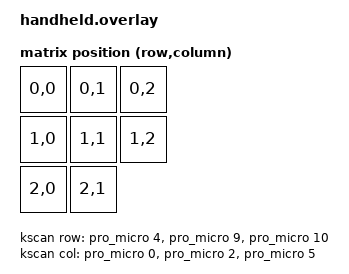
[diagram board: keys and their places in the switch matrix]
// This file was generated from a template. Edit it to match your keyboard.
// See https://zmk.dev/docs/development/hardware-integration/new-shield for more
// instructions.

#include <dt-bindings/zmk/matrix_transform.h>

#include "handheld-layouts.dtsi"

/ {
    chosen {
        zmk,physical-layout = &default_layout;
    };

    kscan: kscan {
        compatible = "zmk,kscan-gpio-matrix";
        diode-direction = "col2row";
        wakeup-source;

        // Replace these comments with the GPIO pins in the matrix.
        // See https://zmk.dev/docs/development/hardware-integration/new-shield#shield-overlays
        col-gpios
            = <&pro_micro 0 GPIO_ACTIVE_HIGH>
            , <&pro_micro 2 GPIO_ACTIVE_HIGH>
            , <&pro_micro 5 GPIO_ACTIVE_HIGH>
            ;

        row-gpios
            = <&pro_micro 4 (GPIO_ACTIVE_HIGH | GPIO_PULL_DOWN)>
            , <&pro_micro 9 (GPIO_ACTIVE_LOW | GPIO_PULL_DOWN)> 
            , <&pro_micro 10 (GPIO_ACTIVE_HIGH | GPIO_PULL_DOWN)>
            ;
    };

    default_transform: default_transform {
        compatible = "zmk,matrix-transform";
        columns = <3>;
        rows = <3>;

        map = <
            RC(0, 0) RC(0, 1) RC(0, 2)
            RC(1, 0) RC(1, 1) RC(1, 2)
            RC(2, 0) RC(2, 1)
        >;
    };
};
